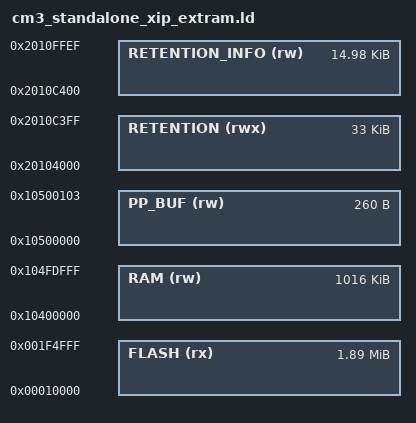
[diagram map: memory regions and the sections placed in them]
MEMORY
{
	FLASH (rx) 	    : ORIGIN = 0x00010000, LENGTH = FLASH_SIZE
	RAM (rw)  	    : ORIGIN = 0x10400000, LENGTH = 1024K - STACK_SIZE
	PP_BUF (rw)  	    : ORIGIN = 0x10500000, LENGTH = 260
	RETENTION (rwx)     : ORIGIN = 0x20104000, LENGTH = 33K
	RETENTION_INFO(rw)  : ORIGIN = 0x2010C400, LENGTH = 15K - UCODE_HDR_SIZE
}
FLASH_SIZE = 1940K;
STACK_SIZE = 8K;
UCODE_HDR_SIZE = 16;

INCLUDE ././lib/modem/cm3_common.ld
